# cmem7 register map
File version: 1.0
Registers are 32-bit, read-write, reset 0x0 unless marked. A register's access mark holds for its fields unless they carry their own. Offsets are from the block's base; [hi:lo] are bit positions; {n}, {i} and the like mark numbered series; 'fields as' and 'values as' point back to an identical list.

## DMA
Base 0x41500000
{0x0+0x58*i} SAR{i} (i=0..7) — Current Source Address of DMA transfer
{0x8+0x58*i} DAR{i} (i=0..7) — Current Destination Address of DMA transfer
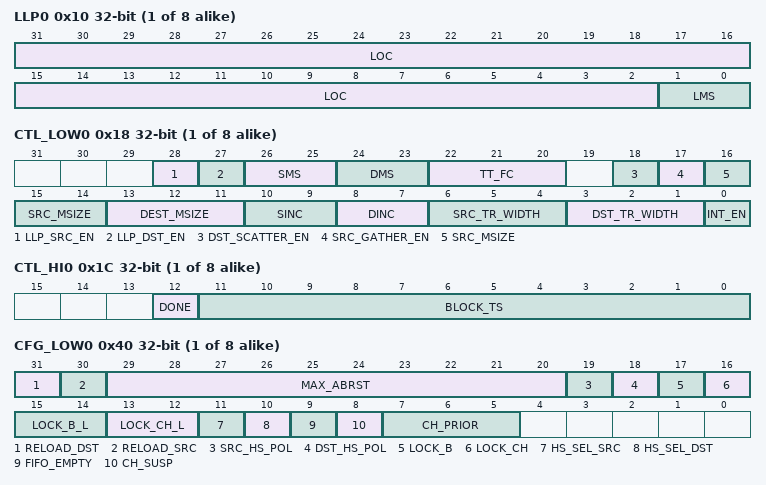
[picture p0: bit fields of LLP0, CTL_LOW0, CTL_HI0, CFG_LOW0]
{0x10+0x58*i} LLP{i} (i=0..7) — Linked List Pointer Register for Channel
  [31:2] LOC — Starting Address In Memory of next LLI if block chaining is enabled
  [1:0] LMS — Identifies the AHB layer/interface where the memory device that stores the next linked list item resides.
    {v}=AHB_MASTER_{v+1} (v=0..3)
{0x18+0x58*i} CTL_LOW{i} (i=0..7) — Lower 32-bits Control Register for Channel
  [28] LLP_SRC_EN — Block chaining is enabled on the source side
  [27] LLP_DST_EN — Block chaining is enabled on the destination side
  [26:25] SMS — Source Master Select
    {v}=AHB_MASTER_{v+1} (v=0..3)
  [24:23] DMS — Destination Master Select
    {v}=AHB_MASTER_{v+1} (v=0..3)
  [22:20] TT_FC — Transfer Type and Flow Control
    0=TT_FC_MM_DW_AHB_DMAC (Transfer Type is memory to memory and Flow Control is DW_ahb_dmac); 1=TT_FC_MP_DW_AHB_DMAC (Transfer Type is memory to peripheral and Flow Control is DW_ahb_dmac); 2=TT_FC_PM_DW_AHB_DMAC (Transfer Type is peripheral to memory and Flow Control is DW_ahb_dmac); 3=TT_FC_PP_DW_AHB_DMAC (Transfer Type is peripheral to peripheral and Flow Control is DW_ahb_dmac); 4=TT_FC_PM_P (Transfer Type is peripheral to memory and Flow Control is peripheral); 5=TT_FC_PP_SP (Transfer Type is peripheral to peripheral and Flow Control is source peripheral); 6=TT_FC_MP_P (Transfer Type is memory to peripheral and Flow Control is peripheral); 7=TT_FC_PP_DP (Transfer Type is peripheral to peripheral and Flow Control is Destination peripheral)
  [18] DST_SCATTER_EN — Destination scatter enable bit
  [17] SRC_GATHER_EN — Source gather enable bit
  [16:14] SRC_MSIZE — Source Burst Transaction Length
    0=MSIZE_1 (1 TR_WIDTH); 1=MSIZE_4 (4 TR_WIDTH); 2=MSIZE_8 (8 TR_WIDTH); 3=MSIZE_16 (16 TR_WIDTH); 4=MSIZE_32 (32 TR_WIDTH); 5=MSIZE_64 (64 TR_WIDTH); 6=MSIZE_128 (128 TR_WIDTH); 7=MSIZE_256 (256 TR_WIDTH)
  [13:11] DEST_MSIZE — Destination Burst Transaction Length
    values as SRC_MSIZE
  [10:9] SINC — Source Address Increment
    0=INC_INCREMENT (Increment); 1=INC_DECREMENT (Decrement); 2=INC_NO_CHANGE (No change)
  [8:7] DINC — Destination Address Increment
    values as SINC
  [6:4] SRC_TR_WIDTH — Source Transfer Width
    0=TR_WIDTH_8_BIT (8 bit); 1=TR_WIDTH_16_BIT (16 bit); 2=TR_WIDTH_32_BIT (32 bit); 3=TR_WIDTH_64_BIT (64 bit); 4=TR_WIDTH_128_BIT (128 bit); 5=TR_WIDTH_256_BIT (256 bit)
  [3:1] DST_TR_WIDTH — Destination Transfer Width
    values as SRC_TR_WIDTH
  [0] INT_EN — Interrupt Enable Bit
{0x1C+0x58*i} CTL_HI{i} (i=0..7) — Higher 32-bits Control Register for Channel
  [12] DONE — a block transfer is complete
  [11:0] BLOCK_TS — indicates the total number of single transactions to perform for every block transfer
{0x20+0x58*i} SSTAT{i} (i=0..7) — Source Status Register for Channel
{0x28+0x58*i} DSTAT{i} (i=0..7) — Destination Status Register for Channel
{0x30+0x58*i} SSTATAR{i} (i=0..7) — Source Status Address Register for Channel
{0x38+0x58*i} DSTATAR{i} (i=0..7) — Destination Status Address Register for Channel
{0x40+0x58*i} CFG_LOW{i} (i=0..7) — Lower 32-bit Configuration Register for Channel
  [31] RELOAD_DST — Automatic Destination Reload
  [30] RELOAD_SRC — Automatic Source Reload
  [29:20] MAX_ABRST — Maximum AMBA Burst Length
  [19] SRC_HS_POL — Source Handshaking Interface Polarity. 0: active high
  [18] DST_HS_POL — Destination Handshaking Interface Polarity. 0: active high
  [17] LOCK_B — Bus Lock Bit
  [16] LOCK_CH — Channel Lock Bit
  [15:14] LOCK_B_L — Indicates the duration over which CFGx.LOCK_B bit applies.
    0=LOCK_L_DMA_TRANSFER (Over complete DMA transfer); 1=LOCK_L_DMA_BLOCK_TRANSFER (Over complete DMA block transfer); 2=LOCK_L_DMA_BLOCK_TRANSACTION (Over complete DMA transaction)
  [13:12] LOCK_CH_L — Indicates the duration over which CFGx.LOCK_CH bit applies.
    values as LOCK_B_L
  [11] HS_SEL_SRC — If Source Software handshaking interface
  [10] HS_SEL_DST — If Destination Software handshaking interface
  [9] FIFO_EMPTY ro — Indicates if there is data left in the channel FIFO
  [8] CH_SUSP — Suspends all DMA data transfers from the source until this bit is cleared.
  [7:5] CH_PRIOR — Channel priority. A priority of 7 is the highest priority
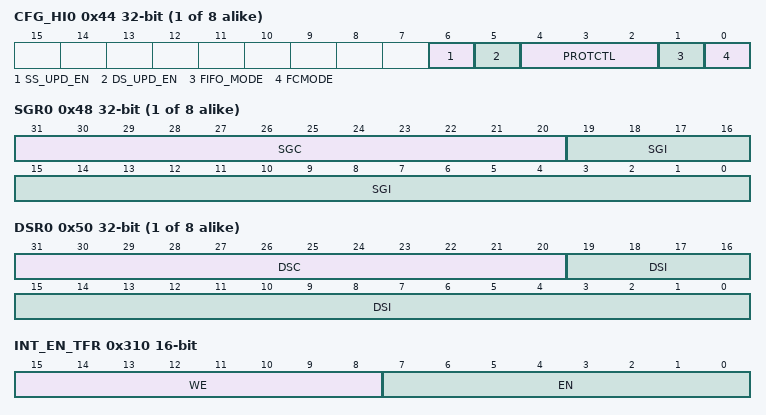
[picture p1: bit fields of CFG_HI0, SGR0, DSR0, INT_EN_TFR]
{0x44+0x58*i} CFG_HI{i} (i=0..7) — Higher 32-bit Configuration Register for Channel
  [6] SS_UPD_EN — STATx is only updated from STATARx
  [5] DS_UPD_EN — STATx is only updated from STATARx
  [4:2] PROTCTL — There is a one-to-one mapping of these register bits to the HPROT[3:1] master interface signals
    0=PROTCTL_HPROT_1 (HPROT[1]); 1=PROTCTL_HPROT_2 (HPROT[2]); 2=PROTCTL_HPROT_3 (HPROT[3])
  [1] FIFO_MODE — Determines space or data needs to be available in the FIFO before a burst transaction request is serviced.
    0=Space/data available for single AHB transfer of the specified transfer width; 1=Data available is greater than half the FIFO depth for destination transfers and space available is greater than half the fifo depth for source transfers
  [0] FCMODE — if source transaction requests aren't serviced when the Destination Peripheral is the flow controller.
{0x48+0x58*i} SGR{i} (i=0..7) — Source Gather Register for Channel
  [31:20] SGC — Specifies the number of contiguous source transfers of CTLx.SRC_TR_WIDTH
  [19:0] SGI — Source gather interval
{0x50+0x58*i} DSR{i} (i=0..7) — Destination Scatter Register for Channel
  [31:20] DSC — Specifies the number of contiguous destination transfers of CTLx.DST_TR_WIDTH
  [19:0] DSI — Destination scatter interval
0x2E8 INT_TFR 8-bit ro — DMA Transfer Complete
0x2F0 INT_BLOCK 8-bit ro — Block Transfer Complete
0x2F8 INT_SRC_TRAN 8-bit ro — Source Transaction Complete
0x300 INT_DST_TRAN 8-bit ro — Destination Transaction Complete
0x308 INT_ERR 8-bit ro — Error
0x310 INT_EN_TFR 16-bit — DMA Transfer Complete
  [15:8] WE — interrupt enable write enable
  [7:0] EN — interrupt enable
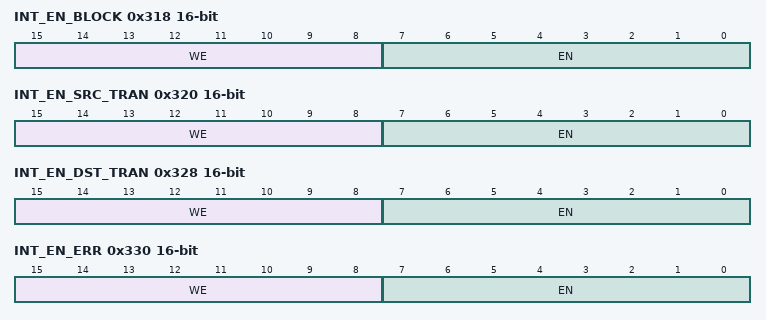
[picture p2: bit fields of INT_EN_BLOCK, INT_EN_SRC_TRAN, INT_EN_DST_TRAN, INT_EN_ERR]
0x318 INT_EN_BLOCK 16-bit — Block Transfer Complete
  fields as INT_EN_TFR
0x320 INT_EN_SRC_TRAN 16-bit — Source Transaction Complete
  fields as INT_EN_TFR
0x328 INT_EN_DST_TRAN 16-bit — Destination Transaction Complete
  fields as INT_EN_TFR
0x330 INT_EN_ERR 16-bit — Error
  fields as INT_EN_TFR
0x338 INT_CLEAR_TFR 8-bit wo — DMA Transfer Complete
0x340 INT_CLEAR_BLOCK 8-bit wo — Block Transfer Complete
0x348 INT_CLEAR_SRC_TRAN 8-bit wo — Source Transaction Complete
0x350 INT_CLEAR_DST_TRAN 8-bit wo — Destination Transaction Complete
0x358 INT_CLEAR_ERR 8-bit wo — Error
0x398 DMA_EN — DW_ahb_dmac Configuration Register
  [0] EN — enable
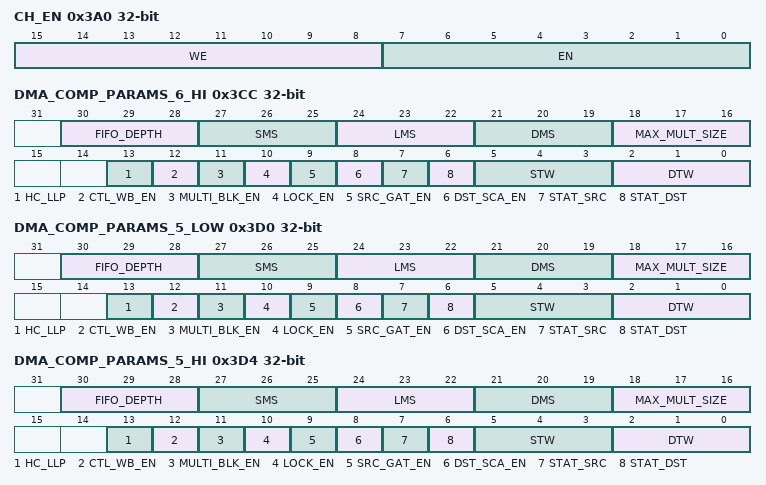
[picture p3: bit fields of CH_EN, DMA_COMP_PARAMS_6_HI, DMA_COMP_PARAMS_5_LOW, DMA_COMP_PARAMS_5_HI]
0x3A0 CH_EN — DW_ahb_dmac Channel Enable Register
  [15:8] WE — enable write enable
  [7:0] EN — enable
0x3CC DMA_COMP_PARAMS_6_HI ro — Component Parameters for channel 7
  [30:28] FIFO_DEPTH — FIFO depth in bytes
    0=8 bytes; 1=16 bytes; 2=32 bytes; 3=64 bytes; 4=128 bytes
  [27:25] SMS — source AHB dma interface
    {v}=AHB_MASTER_{v+1} (v=0..3); 4=AHB_MASTER_NO_HARDCODE (NO_HARDCODE)
  [24:22] LMS — Linked list AHB dma interface
    values as SMS
  [21:19] DMS — Destination AHB dma interface
    values as SMS
  [18:16] MAX_MULT_SIZE — Maximum value of burst transaction size (SRC_MSIZE and DEST_MSIZE).
    0=4; 1=8; 2=16; 3=32; 4=64; 5=128; 6=256
  [13] HC_LLP — If disable LLP feature is on
  [12] CTL_WB_EN — If write back initial values to relative registers feature is on
  [11] MULTI_BLK_EN — If multi blocks transfer feature is on
  [10] LOCK_EN — If channel lock feature is on
  [9] SRC_GAT_EN — If source gather feature is on
  [8] DST_SCA_EN — If destination scatter feature is on
  [7] STAT_SRC — If source status load feature is on
  [6] STAT_DST — If destination status load feature is on
  [5:3] STW — If this is not hardcoded, then software can program the source transfer width.
    0=DTW_HARDCODE_NO (NO_HARDCODE); 1=DTW_HARDCODE_8 (8 bits); 2=DTW_HARDCODE_16 (16 bits); 3=DTW_HARDCODE_32 (32 bits); 4=DTW_HARDCODE_64 (64 bits); 5=DTW_HARDCODE_128 (128 bits); 6=DTW_HARDCODE_256 (256 bits)
  [2:0] DTW — If this is not hardcoded, then software can program the destination transfer width.
    values as STW
0x3D0 DMA_COMP_PARAMS_5_LOW ro — Component Parameters for channel 6
  fields as DMA_COMP_PARAMS_6_HI
0x3D4 DMA_COMP_PARAMS_5_HI ro — Component Parameters for channel 5
  fields as DMA_COMP_PARAMS_6_HI
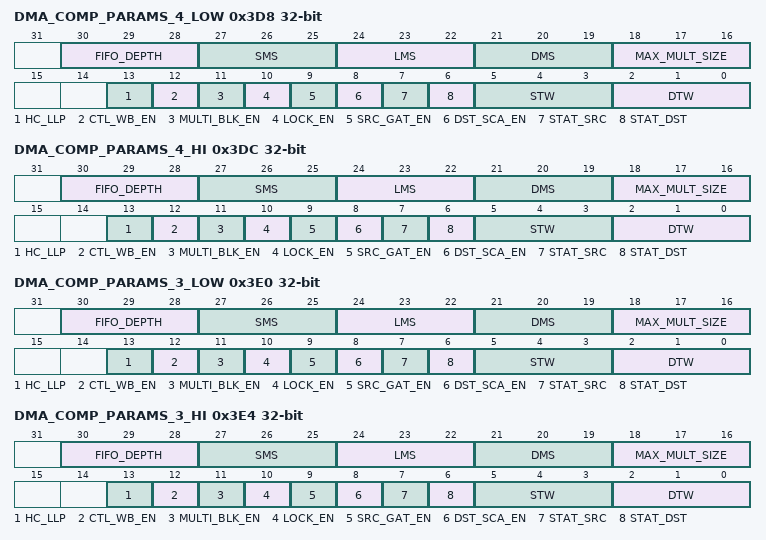
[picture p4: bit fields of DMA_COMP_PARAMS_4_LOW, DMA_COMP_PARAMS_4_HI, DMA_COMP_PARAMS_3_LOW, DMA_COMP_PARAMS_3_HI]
0x3D8 DMA_COMP_PARAMS_4_LOW ro — Component Parameters for channel 4
  fields as DMA_COMP_PARAMS_6_HI
0x3DC DMA_COMP_PARAMS_4_HI ro — Component Parameters for channel 3
  fields as DMA_COMP_PARAMS_6_HI
0x3E0 DMA_COMP_PARAMS_3_LOW ro — Component Parameters for channel 2
  fields as DMA_COMP_PARAMS_6_HI
0x3E4 DMA_COMP_PARAMS_3_HI ro — Component Parameters for channel 1
  fields as DMA_COMP_PARAMS_6_HI
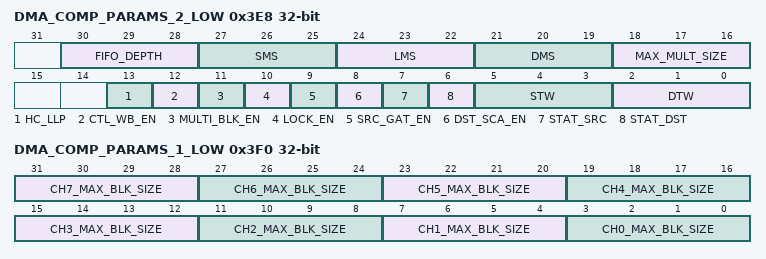
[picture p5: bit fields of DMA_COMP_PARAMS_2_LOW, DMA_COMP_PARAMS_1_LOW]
0x3E8 DMA_COMP_PARAMS_2_LOW ro — Component Parameters for channel 0
  fields as DMA_COMP_PARAMS_6_HI
0x3F0 DMA_COMP_PARAMS_1_LOW ro — Maximum block size for channel
  [all] fields
    0=MAX_BLK_SIZE_3 (3); 1=MAX_BLK_SIZE_7 (7); 2=MAX_BLK_SIZE_15 (15); 3=MAX_BLK_SIZE_31 (31); 4=MAX_BLK_SIZE_63 (63); 5=MAX_BLK_SIZE_127 (127); 6=MAX_BLK_SIZE_255 (255); 7=MAX_BLK_SIZE_511 (511); 8=MAX_BLK_SIZE_1023 (1023); 9=MAX_BLK_SIZE_2047 (2047); 10=MAX_BLK_SIZE_4095 (4095)
  [4n+3:4n] CH{n}_MAX_BLK_SIZE (n=1..7) — Maximum block size for channel {n}
  [3:0] CH0_MAX_BLK_SIZE — Maximum block size for channel 0.
